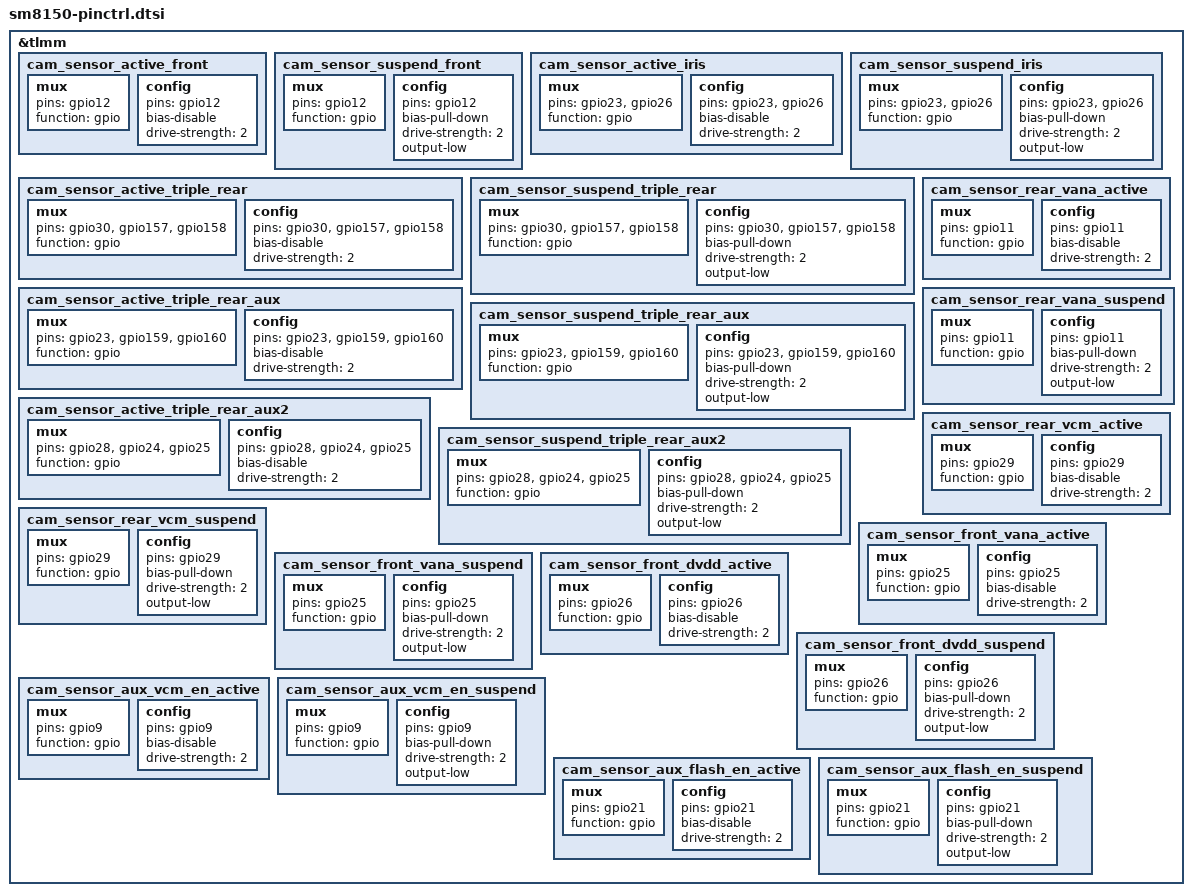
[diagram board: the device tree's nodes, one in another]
&tlmm {
	cam_sensor_active_front: cam_sensor_active_front {
	    /* RESET FRONT */
	    mux {
		pins = "gpio12";
		function = "gpio";
	    };

	    config {
		pins = "gpio12";
		bias-disable; /* No PULL */
		drive-strength = <2>; /* 2 MA */
	    };
	};

	cam_sensor_suspend_front: cam_sensor_suspend_front {
	    /* RESET FRONT */
	    mux {
		pins = "gpio12";
		function = "gpio";
	    };

	    config {
		pins = "gpio12";
		bias-pull-down; /* PULL DOWN */
		drive-strength = <2>; /* 2 MA */
		output-low;
	    };
	};

	cam_sensor_active_iris: cam_sensor_active_iris {
	    /* RESET IRIS */
	    mux {
		pins = "gpio23", "gpio26";
		function = "gpio";
	    };

	    config {
		pins = "gpio23", "gpio26";
		bias-disable; /* No PULL */
		drive-strength = <2>; /* 2 MA */
	    };
	};

	cam_sensor_suspend_iris: cam_sensor_suspend_iris {
	    /* RESET IRIS */
	    mux {
		pins = "gpio23", "gpio26";
		function = "gpio";
	    };

	    config {
		pins = "gpio23", "gpio26";
		bias-pull-down; /* PULL DOWN */
		drive-strength = <2>; /* 2 MA */
		output-low;
	    };
	};

	cam_sensor_active_triple_rear: cam_sensor_active_triple_rear {
	    mux {
		pins = "gpio30", "gpio157", "gpio158";
		function = "gpio";
	    };

	    config {
		pins = "gpio30", "gpio157", "gpio158";
		bias-disable; /* No PULL */
		drive-strength = <2>; /* 2 MA */
	    };
	};

	cam_sensor_suspend_triple_rear: cam_sensor_suspend_triple_rear {
	    mux {
		pins = "gpio30", "gpio157", "gpio158";
		function = "gpio";
	    };

	    config {
		pins = "gpio30", "gpio157", "gpio158";
		bias-pull-down; /* PULL DOWN */
		drive-strength = <2>; /* 2 MA */
		output-low;
	    };
	};

	cam_sensor_active_triple_rear_aux:
	    cam_sensor_active_triple_rear_aux {
	    mux {
		pins = "gpio23", "gpio159", "gpio160";
		function = "gpio";
	    };

	    config {
		pins = "gpio23", "gpio159", "gpio160";
		bias-disable; /* No PULL */
		drive-strength = <2>; /* 2 MA */
	    };
	};

	cam_sensor_suspend_triple_rear_aux:
	    cam_sensor_suspend_triple_rear_aux {
	    mux {
		pins = "gpio23", "gpio159", "gpio160";
		function = "gpio";
	    };

	    config {
		pins = "gpio23", "gpio159", "gpio160";
		bias-pull-down; /* PULL DOWN */
		drive-strength = <2>; /* 2 MA */
		output-low;
	    };
	};

	cam_sensor_active_triple_rear_aux2:
	    cam_sensor_active_triple_rear_aux2 {
	    mux {
		pins = "gpio28", "gpio24", "gpio25";
		function = "gpio";
	    };

	    config {
		pins = "gpio28", "gpio24", "gpio25";
		bias-disable; /* No PULL */
		drive-strength = <2>; /* 2 MA */
	    };
	};

	cam_sensor_suspend_triple_rear_aux2:
	    cam_sensor_suspend_triple_rear_aux2 {
	    mux {
		pins = "gpio28", "gpio24", "gpio25";
		function = "gpio";
	    };

	    config {
		pins = "gpio28", "gpio24", "gpio25";
		bias-pull-down; /* PULL DOWN */
		drive-strength = <2>; /* 2 MA */
		output-low;
	    };
	};

	cam_sensor_rear_vana_active: cam_sensor_rear_vana_active {
	    /*  AVDD LDO */
	    mux {
		pins = "gpio11";
		function = "gpio";
	    };

	    config {
		pins = "gpio11";
		bias-disable; /* No PULL */
		drive-strength = <2>; /* 2 MA */
	    };
	};

	cam_sensor_rear_vana_suspend: cam_sensor_rear_vana_suspend {
	    /*  AVDD LDO */
	    mux {
		pins = "gpio11";
		function = "gpio";
	    };

	    config {
		pins = "gpio11";
		bias-pull-down; /* PULL DOWN */
		drive-strength = <2>; /* 2 MA */
		output-low;
	    };
	};

	cam_sensor_rear_vcm_active: cam_sensor_rear_vcm_active {
	    /*  VCM LDO ENABLE */
	    mux {
		pins = "gpio29";
		function = "gpio";
	    };

	    config {
		pins = "gpio29";
		bias-disable; /* No PULL */
		drive-strength = <2>; /* 2 MA */
	    };
	};

	cam_sensor_rear_vcm_suspend: cam_sensor_rear_vcm_suspend {
	    /*  VCM LDO ENABLE */
	    mux {
		pins = "gpio29";
		function = "gpio";
	    };

	    config {
		pins = "gpio29";
		bias-pull-down; /* PULL DOWN */
		drive-strength = <2>; /* 2 MA */
		output-low;
	    };
	};

	cam_sensor_front_vana_active: cam_sensor_front_vana_active {
	    /*  AVDD LDO */
	    mux {
		pins = "gpio25";
		function = "gpio";
	    };

	    config {
		pins = "gpio25";
		bias-disable; /* No PULL */
		drive-strength = <2>; /* 2 MA */
	    };
	};

	cam_sensor_front_vana_suspend: cam_sensor_front_vana_suspend {
	    /*  AVDD LDO */
	    mux {
		pins = "gpio25";
		function = "gpio";
	    };

	    config {
		pins = "gpio25";
		bias-pull-down; /* PULL DOWN */
		drive-strength = <2>; /* 2 MA */
		output-low;
	    };
	};

	cam_sensor_front_dvdd_active: cam_sensor_front_dvdd_active {
	    /*  DVDD LDO */
	    mux {
		pins = "gpio26";
		function = "gpio";
	    };

	    config {
		pins = "gpio26";
		bias-disable; /* No PULL */
		drive-strength = <2>; /* 2 MA */
	    };
	};

	cam_sensor_front_dvdd_suspend: cam_sensor_front_dvdd_suspend {
	    /*  DVDD LDO */
	    mux {
		pins = "gpio26";
		function = "gpio";
	    };

	    config {
		pins = "gpio26";
		bias-pull-down; /* PULL DOWN */
		drive-strength = <2>; /* 2 MA */
		output-low;
	    };
	};

	cam_sensor_aux_vcm_en_active: cam_sensor_aux_vcm_en_active {
	    /*  DVDD LDO */
	    mux {
		pins = "gpio9";
		function = "gpio";
	    };

	    config {
		pins = "gpio9";
		bias-disable; /* No PULL */
		drive-strength = <2>; /* 2 MA */
	    };
	};

	cam_sensor_aux_vcm_en_suspend: cam_sensor_aux_vcm_en_suspend {
	    /*  DVDD LDO */
	    mux {
		pins = "gpio9";
		function = "gpio";
	    };

	    config {
		pins = "gpio9";
		bias-pull-down; /* PULL DOWN */
		drive-strength = <2>; /* 2 MA */
		output-low;
	    };
	};

	cam_sensor_aux_flash_en_active: cam_sensor_aux_flash_en_active {
	    /*  DVDD LDO */
	    mux {
		pins = "gpio21";
		function = "gpio";
	    };

	    config {
		pins = "gpio21";
		bias-disable; /* No PULL */
		drive-strength = <2>; /* 2 MA */
	    };
	};

	cam_sensor_aux_flash_en_suspend: cam_sensor_aux_flash_en_suspend {
	    /*  DVDD LDO */
	    mux {
		pins = "gpio21";
		function = "gpio";
	    };

	    config {
		pins = "gpio21";
		bias-pull-down; /* PULL DOWN */
		drive-strength = <2>; /* 2 MA */
		output-low;
	    };
	};
};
